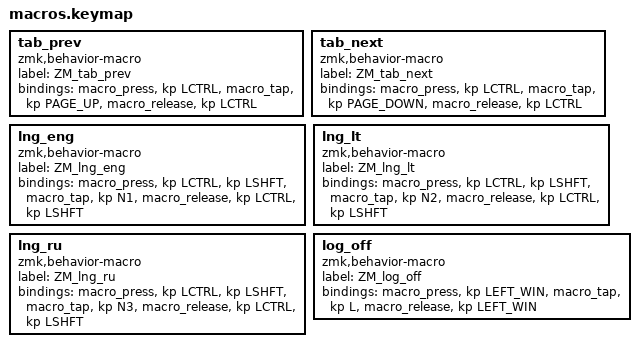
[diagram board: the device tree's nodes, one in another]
tab_prev: tab_prev {
        label = "ZM_tab_prev";
        compatible = "zmk,behavior-macro";
        #binding-cells = <0>;
        bindings
                = <&macro_press &kp LCTRL>
                , <&macro_tap &kp PAGE_UP>
                , <&macro_release &kp LCTRL>;
};

tab_next: tab_next {
        label = "ZM_tab_next";
        compatible = "zmk,behavior-macro";
        #binding-cells = <0>;
        bindings
                = <&macro_press &kp LCTRL>
                , <&macro_tap &kp PAGE_DOWN>
                , <&macro_release &kp LCTRL>;
};

lng_eng: lng_eng {
        label = "ZM_lng_eng";
        compatible = "zmk,behavior-macro";
        #binding-cells = <0>;
        bindings
                = <&macro_press &kp LCTRL &kp LSHFT>
                , <&macro_tap &kp N1>
                , <&macro_release &kp LCTRL &kp LSHFT>;
};

lng_lt: lng_lt {
        label = "ZM_lng_lt";
        compatible = "zmk,behavior-macro";
        #binding-cells = <0>;
        bindings
                = <&macro_press &kp LCTRL &kp LSHFT>
                , <&macro_tap &kp N2>
                , <&macro_release &kp LCTRL &kp LSHFT>;
};

lng_ru: lng_ru {
        label = "ZM_lng_ru";
        compatible = "zmk,behavior-macro";
        #binding-cells = <0>;
        bindings
                = <&macro_press &kp LCTRL &kp LSHFT>
                , <&macro_tap &kp N3>
                , <&macro_release &kp LCTRL &kp LSHFT>;
};

log_off: log_off {
        label = "ZM_log_off";
        compatible = "zmk,behavior-macro";
        #binding-cells = <0>;
        bindings
                = <&macro_press &kp LEFT_WIN>
                , <&macro_tap &kp L>
                , <&macro_release &kp LEFT_WIN>;
};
